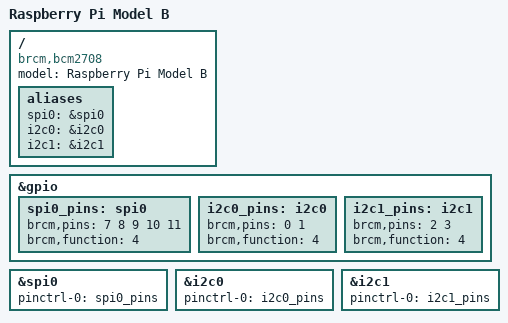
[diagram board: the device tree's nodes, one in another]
/include/ "bcm2708.dtsi"

/ {
	compatible = "brcm,bcm2708";
	model = "Raspberry Pi Model B";

	aliases {
		spi0 = &spi0;
		i2c0 = &i2c0;
		i2c1 = &i2c1;
	};
};

&gpio {
	spi0_pins: spi0 {
		brcm,pins = <7 8 9 10 11>;
		brcm,function = <4>; /* alt0 */
	};

	i2c0_pins: i2c0 {
		brcm,pins = <0 1>;
		brcm,function = <4>; /* alt0 */
	};

	i2c1_pins: i2c1 {
		brcm,pins = <2 3>;
		brcm,function = <4>; /* alt0 */
	};
};

&spi0 {
	pinctrl-names = "default";
	pinctrl-0 = <&spi0_pins>;
};

&i2c0 {
	pinctrl-names = "default";
	pinctrl-0 = <&i2c0_pins>;
};

&i2c1 {
	pinctrl-names = "default";
	pinctrl-0 = <&i2c1_pins>;
};
